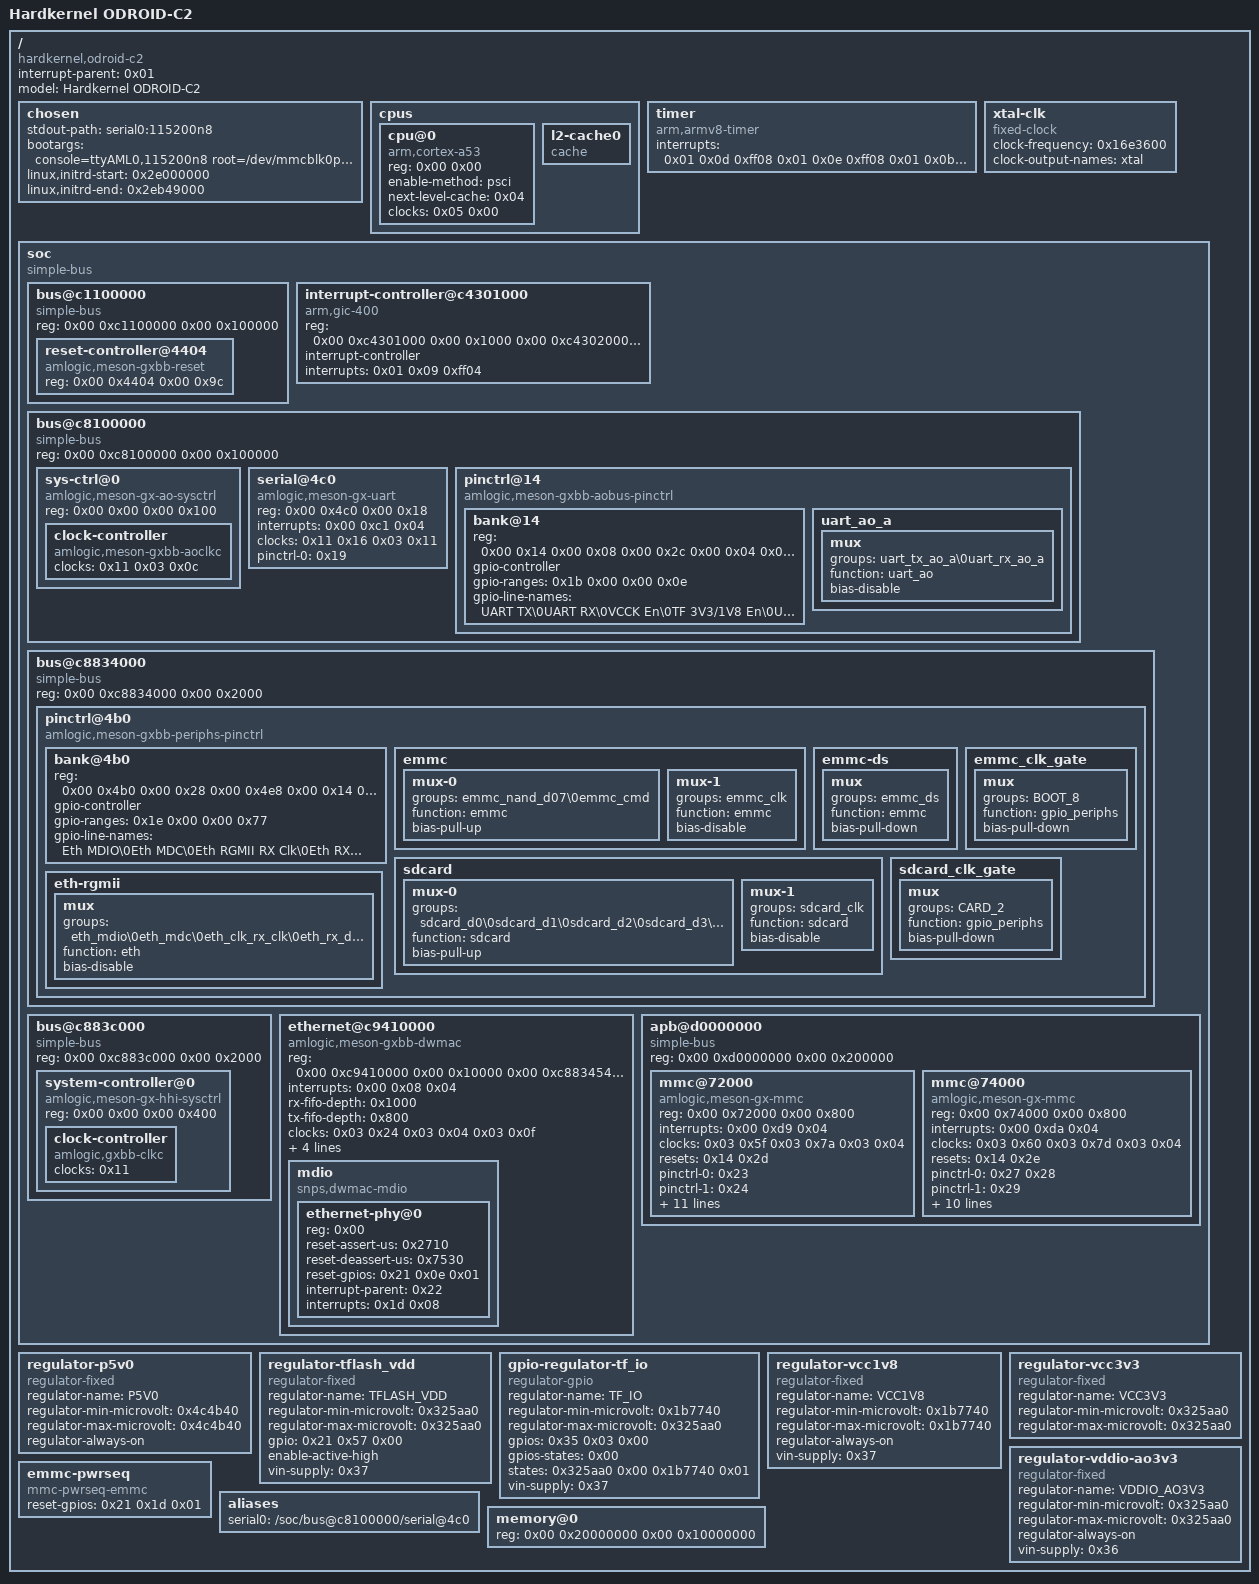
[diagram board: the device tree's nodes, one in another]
/dts-v1/;

/ {
	interrupt-parent = <0x01>;
	#address-cells = <0x02>;
	#size-cells = <0x02>;
	compatible = "hardkernel,odroid-c2\0amlogic,meson-gxbb";
	model = "Hardkernel ODROID-C2";

	chosen {
		#address-cells = <0x02>;
		#size-cells = <0x02>;
		ranges;
		stdout-path = "serial0:115200n8";
		bootargs = "console=ttyAML0,115200n8 root=/dev/mmcblk0p1 rootwait rw nosmp debug loglevel=8 pci=nomsi earlycon=meson,0xc81004c0 earlyprintk=serial maxcpus=1";
		linux,initrd-start = <0x2e000000>;
		linux,initrd-end = <0x2eb49000>;
	};

	cpus {
		#address-cells = <0x02>;
		#size-cells = <0x00>;

		cpu@0 {
			device_type = "cpu";
			compatible = "arm,cortex-a53";
			reg = <0x00 0x00>;
			enable-method = "psci";
			next-level-cache = <0x04>;
			clocks = <0x05 0x00>;
			#cooling-cells = <0x02>;
			phandle = <0x08>;
		};

		l2-cache0 {
			compatible = "cache";
			phandle = <0x04>;
		};
	};

	timer {
		compatible = "arm,armv8-timer";
		interrupts = <0x01 0x0d 0xff08 0x01 0x0e 0xff08 0x01 0x0b 0xff08 0x01 0x0a 0xff08>;
	};

	xtal-clk {
		compatible = "fixed-clock";
		clock-frequency = <0x16e3600>;
		clock-output-names = "xtal";
		#clock-cells = <0x00>;
		phandle = <0x11>;
	};

	soc {
		compatible = "simple-bus";
		#address-cells = <0x02>;
		#size-cells = <0x02>;
		ranges;

		bus@c1100000 {
			compatible = "simple-bus";
			reg = <0x00 0xc1100000 0x00 0x100000>;
			#address-cells = <0x02>;
			#size-cells = <0x02>;
			ranges = <0x00 0x00 0x00 0xc1100000 0x00 0x100000>;

			reset-controller@4404 {
				compatible = "amlogic,meson-gxbb-reset";
				reg = <0x00 0x4404 0x00 0x9c>;
				#reset-cells = <0x01>;
				phandle = <0x14>;
			};
		};

		interrupt-controller@c4301000 {
			compatible = "arm,gic-400";
			reg = <0x00 0xc4301000 0x00 0x1000 0x00 0xc4302000 0x00 0x2000 0x00 0xc4304000 0x00 0x2000 0x00 0xc4306000 0x00 0x2000>;
			interrupt-controller;
			interrupts = <0x01 0x09 0xff04>;
			#interrupt-cells = <0x03>;
			#address-cells = <0x00>;
			phandle = <0x01>;
		};

		bus@c8100000 {
			compatible = "simple-bus";
			reg = <0x00 0xc8100000 0x00 0x100000>;
			#address-cells = <0x02>;
			#size-cells = <0x02>;
			ranges = <0x00 0x00 0x00 0xc8100000 0x00 0x100000>;

			sys-ctrl@0 {
				compatible = "amlogic,meson-gx-ao-sysctrl\0simple-mfd\0syscon";
				reg = <0x00 0x00 0x00 0x100>;
				phandle = <0x1c>;

				clock-controller {
					compatible = "amlogic,meson-gxbb-aoclkc\0amlogic,meson-gx-aoclkc";
					#clock-cells = <0x01>;
					#reset-cells = <0x01>;
					clocks = <0x11 0x03 0x0c>;
					clock-names = "xtal\0mpeg-clk";
					phandle = <0x16>;
				};
			};

			serial@4c0 {
				compatible = "amlogic,meson-gx-uart\0amlogic,meson-ao-uart";
				reg = <0x00 0x4c0 0x00 0x18>;
				interrupts = <0x00 0xc1 0x04>;
				status = "okay";
				clocks = <0x11 0x16 0x03 0x11>;
				clock-names = "xtal\0pclk\0baud";
				pinctrl-0 = <0x19>;
				pinctrl-names = "default";
			};

			pinctrl@14 {
				compatible = "amlogic,meson-gxbb-aobus-pinctrl";
				#address-cells = <0x02>;
				#size-cells = <0x02>;
				ranges;
				phandle = <0x1b>;

				bank@14 {
					reg = <0x00 0x14 0x00 0x08 0x00 0x2c 0x00 0x04 0x00 0x24 0x00 0x08>;
					reg-names = "mux\0pull\0gpio";
					gpio-controller;
					#gpio-cells = <0x02>;
					gpio-ranges = <0x1b 0x00 0x00 0x0e>;
					gpio-line-names = "UART TX\0UART RX\0VCCK En\0TF 3V3/1V8 En\0USB HUB nRESET\0USB OTG Power En\0J7 Header Pin2\0IR In\0J7 Header Pin4\0J7 Header Pin6\0J7 Header Pin5\0J7 Header Pin7\0HDMI CEC\0SYS LED\0";
					phandle = <0x35>;
				};

				uart_ao_a {
					phandle = <0x19>;

					mux {
						groups = "uart_tx_ao_a\0uart_rx_ao_a";
						function = "uart_ao";
						bias-disable;
					};
				};
			};
		};

		bus@c8834000 {
			compatible = "simple-bus";
			reg = <0x00 0xc8834000 0x00 0x2000>;
			#address-cells = <0x02>;
			#size-cells = <0x02>;
			ranges = <0x00 0x00 0x00 0xc8834000 0x00 0x2000>;

			pinctrl@4b0 {
				compatible = "amlogic,meson-gxbb-periphs-pinctrl";
				#address-cells = <0x02>;
				#size-cells = <0x02>;
				ranges;
				phandle = <0x1e>;

				bank@4b0 {
					reg = <0x00 0x4b0 0x00 0x28 0x00 0x4e8 0x00 0x14 0x00 0x520 0x00 0x14 0x00 0x430 0x00 0x40>;
					reg-names = "mux\0pull\0pull-enable\0gpio";
					gpio-controller;
					#gpio-cells = <0x02>;
					gpio-ranges = <0x1e 0x00 0x00 0x77>;
					gpio-line-names = "Eth MDIO\0Eth MDC\0Eth RGMII RX Clk\0Eth RX DV\0Eth RX D0\0Eth RX D1\0Eth RX D2\0Eth RX D3\0Eth RGMII TX Clk\0Eth TX En\0Eth TX D0\0Eth TX D1\0Eth TX D2\0Eth TX D3\0Eth PHY nRESET\0Eth PHY Intc\0HDMI HPD\0HDMI DDC SDA\0HDMI DDC SCL\0\0eMMC D0\0eMMC D1\0eMMC D2\0eMMC D3\0eMMC D4\0eMMC D5\0eMMC D6\0eMMC D7\0eMMC Clk\0eMMC Reset\0eMMC CMD\0\0\0\0\0\0\0\0SDCard D1\0SDCard D0\0SDCard CLK\0SDCard CMD\0SDCard D3\0SDCard D2\0SDCard Det\0\0\0\0\0\0\0\0\0\0\0\0\0\0\0\0\0\0\0\0\0\0\0\0\0I2C A SDA\0I2C A SCK\0I2C B SDA\0I2C B SCK\0PWM D\0PWM B\0Revision Bit0\0Revision Bit1\0\0J2 Header Pin35\0\0\0\0J2 Header Pin36\0J2 Header Pin31\0\0\0\0TF VDD En\0J2 Header Pin32\0J2 Header Pin26\0\0\0J2 Header Pin29\0J2 Header Pin24\0J2 Header Pin23\0J2 Header Pin22\0J2 Header Pin21\0J2 Header Pin18\0J2 Header Pin33\0J2 Header Pin19\0J2 Header Pin16\0J2 Header Pin15\0J2 Header Pin12\0J2 Header Pin13\0J2 Header Pin8\0J2 Header Pin10\0\0\0\0\0\0J2 Header Pin11\0\0J2 Header Pin7\0\0\0\0\0";
					phandle = <0x21>;
				};

				emmc {
					phandle = <0x27>;

					mux-0 {
						groups = "emmc_nand_d07\0emmc_cmd";
						function = "emmc";
						bias-pull-up;
					};

					mux-1 {
						groups = "emmc_clk";
						function = "emmc";
						bias-disable;
					};
				};

				emmc-ds {
					phandle = <0x28>;

					mux {
						groups = "emmc_ds";
						function = "emmc";
						bias-pull-down;
					};
				};

				emmc_clk_gate {
					phandle = <0x29>;

					mux {
						groups = "BOOT_8";
						function = "gpio_periphs";
						bias-pull-down;
					};
				};

				sdcard {
					phandle = <0x23>;

					mux-0 {
						groups = "sdcard_d0\0sdcard_d1\0sdcard_d2\0sdcard_d3\0sdcard_cmd";
						function = "sdcard";
						bias-pull-up;
					};

					mux-1 {
						groups = "sdcard_clk";
						function = "sdcard";
						bias-disable;
					};
				};

				sdcard_clk_gate {
					phandle = <0x24>;

					mux {
						groups = "CARD_2";
						function = "gpio_periphs";
						bias-pull-down;
					};
				};

				eth-rgmii {
					phandle = <0x1f>;

					mux {
						groups = "eth_mdio\0eth_mdc\0eth_clk_rx_clk\0eth_rx_dv\0eth_rxd0\0eth_rxd1\0eth_rxd2\0eth_rxd3\0eth_rgmii_tx_clk\0eth_tx_en\0eth_txd0\0eth_txd1\0eth_txd2\0eth_txd3";
						function = "eth";
						bias-disable;
					};
				};
			};
		};

		bus@c883c000 {
			compatible = "simple-bus";
			reg = <0x00 0xc883c000 0x00 0x2000>;
			#address-cells = <0x02>;
			#size-cells = <0x02>;
			ranges = <0x00 0x00 0x00 0xc883c000 0x00 0x2000>;

			system-controller@0 {
				compatible = "amlogic,meson-gx-hhi-sysctrl\0simple-mfd\0syscon";
				reg = <0x00 0x00 0x00 0x400>;
				phandle = <0x15>;

				clock-controller {
					compatible = "amlogic,gxbb-clkc";
					#clock-cells = <0x01>;
					clocks = <0x11>;
					clock-names = "xtal";
					phandle = <0x03>;
				};
			};
		};

		ethernet@c9410000 {
			compatible = "amlogic,meson-gxbb-dwmac\0snps,dwmac-3.70a\0snps,dwmac";
			reg = <0x00 0xc9410000 0x00 0x10000 0x00 0xc8834540 0x00 0x04>;
			interrupts = <0x00 0x08 0x04>;
			interrupt-names = "macirq";
			rx-fifo-depth = <0x1000>;
			tx-fifo-depth = <0x800>;
			status = "okay";
			clocks = <0x03 0x24 0x03 0x04 0x03 0x0f>;
			clock-names = "stmmaceth\0clkin0\0clkin1";
			pinctrl-0 = <0x1f>;
			pinctrl-names = "default";
			phy-handle = <0x20>;
			phy-mode = "rgmii";
			amlogic,tx-delay-ns = <0x02>;

			mdio {
				compatible = "snps,dwmac-mdio";
				#address-cells = <0x01>;
				#size-cells = <0x00>;

				ethernet-phy@0 {
					reg = <0x00>;
					reset-assert-us = <0x2710>;
					reset-deassert-us = <0x7530>;
					reset-gpios = <0x21 0x0e 0x01>;
					interrupt-parent = <0x22>;
					interrupts = <0x1d 0x08>;
					phandle = <0x20>;
				};
			};
		};

		apb@d0000000 {
			compatible = "simple-bus";
			reg = <0x00 0xd0000000 0x00 0x200000>;
			#address-cells = <0x02>;
			#size-cells = <0x02>;
			ranges = <0x00 0x00 0x00 0xd0000000 0x00 0x200000>;

			mmc@72000 {
				compatible = "amlogic,meson-gx-mmc\0amlogic,meson-gxbb-mmc";
				reg = <0x00 0x72000 0x00 0x800>;
				interrupts = <0x00 0xd9 0x04>;
				status = "okay";
				clocks = <0x03 0x5f 0x03 0x7a 0x03 0x04>;
				clock-names = "core\0clkin0\0clkin1";
				resets = <0x14 0x2d>;
				pinctrl-0 = <0x23>;
				pinctrl-1 = <0x24>;
				pinctrl-names = "default\0clk-gate";
				bus-width = <0x04>;
				cap-sd-highspeed;
				sd-uhs-sdr12;
				sd-uhs-sdr25;
				sd-uhs-sdr50;
				sd-uhs-ddr50;
				max-frequency = <0x5f5e100>;
				disable-wp;
				cd-gpios = <0x21 0x2c 0x01>;
				vmmc-supply = <0x25>;
				vqmmc-supply = <0x26>;
			};

			mmc@74000 {
				compatible = "amlogic,meson-gx-mmc\0amlogic,meson-gxbb-mmc";
				reg = <0x00 0x74000 0x00 0x800>;
				interrupts = <0x00 0xda 0x04>;
				status = "okay";
				clocks = <0x03 0x60 0x03 0x7d 0x03 0x04>;
				clock-names = "core\0clkin0\0clkin1";
				resets = <0x14 0x2e>;
				pinctrl-0 = <0x27 0x28>;
				pinctrl-1 = <0x29>;
				pinctrl-names = "default\0clk-gate";
				bus-width = <0x08>;
				max-frequency = <0xbebc200>;
				non-removable;
				disable-wp;
				cap-mmc-highspeed;
				mmc-ddr-1_8v;
				mmc-hs200-1_8v;
				mmc-pwrseq = <0x2a>;
				vmmc-supply = <0x2b>;
				vqmmc-supply = <0x13>;
			};
		};
	};

	regulator-p5v0 {
		compatible = "regulator-fixed";
		regulator-name = "P5V0";
		regulator-min-microvolt = <0x4c4b40>;
		regulator-max-microvolt = <0x4c4b40>;
		regulator-always-on;
		phandle = <0x36>;
	};

	regulator-tflash_vdd {
		compatible = "regulator-fixed";
		regulator-name = "TFLASH_VDD";
		regulator-min-microvolt = <0x325aa0>;
		regulator-max-microvolt = <0x325aa0>;
		gpio = <0x21 0x57 0x00>;
		enable-active-high;
		vin-supply = <0x37>;
		phandle = <0x25>;
	};

	gpio-regulator-tf_io {
		compatible = "regulator-gpio";
		regulator-name = "TF_IO";
		regulator-min-microvolt = <0x1b7740>;
		regulator-max-microvolt = <0x325aa0>;
		gpios = <0x35 0x03 0x00>;
		gpios-states = <0x00>;
		states = <0x325aa0 0x00 0x1b7740 0x01>;
		vin-supply = <0x37>;
		phandle = <0x26>;
	};

	regulator-vcc1v8 {
		compatible = "regulator-fixed";
		regulator-name = "VCC1V8";
		regulator-min-microvolt = <0x1b7740>;
		regulator-max-microvolt = <0x1b7740>;
		regulator-always-on;
		vin-supply = <0x37>;
		phandle = <0x13>;
	};

	regulator-vcc3v3 {
		compatible = "regulator-fixed";
		regulator-name = "VCC3V3";
		regulator-min-microvolt = <0x325aa0>;
		regulator-max-microvolt = <0x325aa0>;
		phandle = <0x2b>;
	};

	regulator-vddio-ao3v3 {
		compatible = "regulator-fixed";
		regulator-name = "VDDIO_AO3V3";
		regulator-min-microvolt = <0x325aa0>;
		regulator-max-microvolt = <0x325aa0>;
		regulator-always-on;
		vin-supply = <0x36>;
		phandle = <0x37>;
	};

	emmc-pwrseq {
		compatible = "mmc-pwrseq-emmc";
		reset-gpios = <0x21 0x1d 0x01>;
		phandle = <0x2a>;
	};

	aliases {
		serial0 = "/soc/bus@c8100000/serial@4c0";
	};

	memory@0 {
		device_type = "memory";
		reg = <0x00 0x20000000 0x00 0x10000000>;
	};
};
